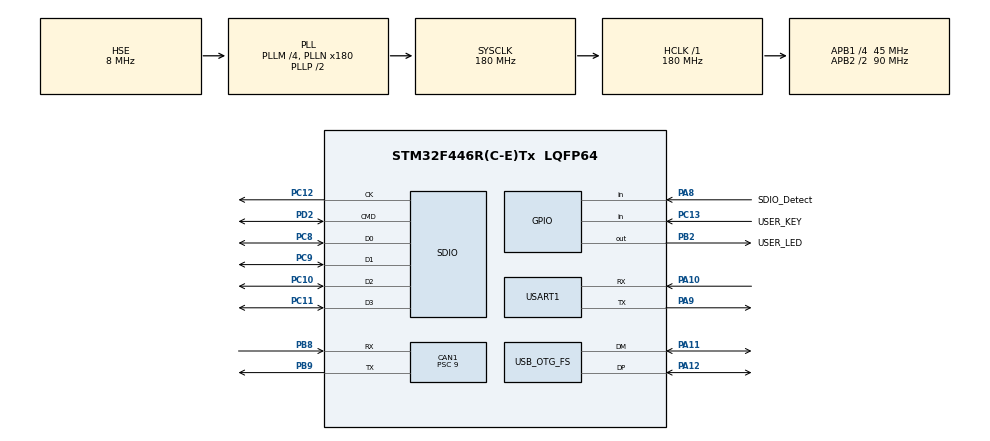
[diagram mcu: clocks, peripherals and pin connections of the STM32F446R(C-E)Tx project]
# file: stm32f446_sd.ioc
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CAN1.BS1=CAN_BS1_13TQ
CAN1.BS2=CAN_BS2_6TQ
CAN1.CalculateBaudRate=250000
CAN1.CalculateTimeBit=4000
CAN1.CalculateTimeQuantum=200.0
CAN1.Mode=CAN_MODE_LOOPBACK
CAN1.Prescaler=9
Dma.Request0=SDIO_RX
Dma.Request1=SDIO_TX
Dma.Request2=USART1_RX
Dma.Request3=USART1_TX
Dma.SDIO_RX.0.Direction=DMA_PERIPH_TO_MEMORY
Dma.SDIO_RX.0.FIFOMode=DMA_FIFOMODE_ENABLE
Dma.SDIO_RX.0.FIFOThreshold=DMA_FIFO_THRESHOLD_FULL
Dma.SDIO_RX.0.Instance=DMA2_Stream3
Dma.SDIO_RX.0.MemBurst=DMA_MBURST_INC4
Dma.SDIO_RX.0.MemDataAlignment=DMA_MDATAALIGN_WORD
Dma.SDIO_RX.0.MemInc=DMA_MINC_ENABLE
Dma.SDIO_RX.0.Mode=DMA_PFCTRL
Dma.SDIO_RX.0.PeriphBurst=DMA_PBURST_INC4
Dma.SDIO_RX.0.PeriphDataAlignment=DMA_PDATAALIGN_WORD
Dma.SDIO_RX.0.PeriphInc=DMA_PINC_DISABLE
Dma.SDIO_RX.0.Priority=DMA_PRIORITY_LOW
Dma.SDIO_TX.1.Direction=DMA_MEMORY_TO_PERIPH
Dma.SDIO_TX.1.FIFOMode=DMA_FIFOMODE_ENABLE
Dma.SDIO_TX.1.FIFOThreshold=DMA_FIFO_THRESHOLD_FULL
Dma.SDIO_TX.1.Instance=DMA2_Stream6
Dma.SDIO_TX.1.MemBurst=DMA_MBURST_INC4
Dma.SDIO_TX.1.MemDataAlignment=DMA_MDATAALIGN_WORD
Dma.SDIO_TX.1.MemInc=DMA_MINC_ENABLE
Dma.SDIO_TX.1.Mode=DMA_PFCTRL
Dma.SDIO_TX.1.PeriphBurst=DMA_PBURST_INC4
Dma.SDIO_TX.1.PeriphDataAlignment=DMA_PDATAALIGN_WORD
Dma.SDIO_TX.1.PeriphInc=DMA_PINC_DISABLE
Dma.SDIO_TX.1.Priority=DMA_PRIORITY_LOW
Dma.USART1_RX.2.Direction=DMA_PERIPH_TO_MEMORY
Dma.USART1_RX.2.FIFOMode=DMA_FIFOMODE_DISABLE
Dma.USART1_RX.2.Instance=DMA2_Stream2
Dma.USART1_RX.2.MemDataAlignment=DMA_MDATAALIGN_BYTE
Dma.USART1_RX.2.MemInc=DMA_MINC_ENABLE
Dma.USART1_RX.2.Mode=DMA_NORMAL
Dma.USART1_RX.2.PeriphDataAlignment=DMA_PDATAALIGN_BYTE
Dma.USART1_RX.2.PeriphInc=DMA_PINC_DISABLE
Dma.USART1_RX.2.Priority=DMA_PRIORITY_LOW
Dma.USART1_TX.3.Direction=DMA_MEMORY_TO_PERIPH
Dma.USART1_TX.3.FIFOMode=DMA_FIFOMODE_DISABLE
Dma.USART1_TX.3.Instance=DMA2_Stream7
Dma.USART1_TX.3.MemDataAlignment=DMA_MDATAALIGN_BYTE
Dma.USART1_TX.3.MemInc=DMA_MINC_ENABLE
Dma.USART1_TX.3.Mode=DMA_NORMAL
Dma.USART1_TX.3.PeriphDataAlignment=DMA_PDATAALIGN_BYTE
Dma.USART1_TX.3.PeriphInc=DMA_PINC_DISABLE
Dma.USART1_TX.3.Priority=DMA_PRIORITY_LOW
FATFS.BSP.number=1
FATFS.USE_DMA_CODE_SD=1
FATFS0.BSP.STBoard=false
FATFS0.BSP.api=Unknown
FATFS0.BSP.instance=PA8
FATFS0.BSP.ip=GPIO
FATFS0.BSP.mode=Input
FATFS0.BSP.name=Detect_SDIO
FATFS0.BSP.solution=PA8
Mcu.Family=STM32F4
Mcu.Name=STM32F446R(C-E)Tx
Mcu.Package=LQFP64
NVIC.DMA2_Stream2_IRQn=true\:0\:0\:false\:false\:true\:false\:true\:true
NVIC.DMA2_Stream3_IRQn=true\:0\:0\:false\:false\:true\:false\:true\:true
NVIC.DMA2_Stream6_IRQn=true\:0\:0\:false\:false\:true\:false\:true\:true
NVIC.DMA2_Stream7_IRQn=true\:0\:0\:false\:false\:true\:false\:true\:true
NVIC.OTG_FS_IRQn=true\:0\:0\:false\:false\:true\:false\:true\:true
NVIC.PriorityGroup=NVIC_PRIORITYGROUP_4
NVIC.SDIO_IRQn=true\:0\:0\:false\:false\:true\:true\:true\:true
NVIC.USART1_IRQn=true\:0\:0\:false\:false\:true\:true\:true\:true
PA10.Mode=Asynchronous
PA10.Signal=USART1_RX
PA11.Mode=Device_Only
PA11.Signal=USB_OTG_FS_DM
PA12.Mode=Device_Only
PA12.Signal=USB_OTG_FS_DP
PA13.Mode=Serial_Wire
PA13.Signal=SYS_JTMS-SWDIO
PA14.Mode=Serial_Wire
PA14.Signal=SYS_JTCK-SWCLK
PA8.GPIO_Label=SDIO_Detect
PA8.GPIO_PuPd=GPIO_PULLUP
PA8.Signal=GPIO_Input
PA9.Mode=Asynchronous
PA9.Signal=USART1_TX
PB2.GPIO_Label=USER_LED
PB2.Signal=GPIO_Output
PB8.Mode=CAN_Activate
PB8.Signal=CAN1_RX
PB9.Mode=CAN_Activate
PB9.Signal=CAN1_TX
PC10.Mode=SD_4_bits_Wide_bus
PC10.Signal=SDIO_D2
PC11.Mode=SD_4_bits_Wide_bus
PC11.Signal=SDIO_D3
PC12.Mode=SD_4_bits_Wide_bus
PC12.Signal=SDIO_CK
PC13.GPIO_Label=USER_KEY
PC13.GPIO_PuPd=GPIO_PULLDOWN
PC13.Signal=GPIO_Input
PC8.Mode=SD_4_bits_Wide_bus
PC8.Signal=SDIO_D0
PC9.Mode=SD_4_bits_Wide_bus
PC9.Signal=SDIO_D1
PD2.Mode=SD_4_bits_Wide_bus
PD2.Signal=SDIO_CMD
PH0-OSC_IN.Mode=HSE-External-Oscillator
PH0-OSC_IN.Signal=RCC_OSC_IN
PH1-OSC_OUT.Mode=HSE-External-Oscillator
PH1-OSC_OUT.Signal=RCC_OSC_OUT
ProjectManager.HeapSize=0x400
ProjectManager.StackSize=0x800
ProjectManager.TargetToolchain=STM32CubeIDE
RCC.AHBFreq_Value=180000000
RCC.APB1CLKDivider=RCC_HCLK_DIV4
RCC.APB1Freq_Value=45000000
RCC.APB1TimFreq_Value=90000000
RCC.APB2CLKDivider=RCC_HCLK_DIV2
RCC.APB2Freq_Value=90000000
RCC.APB2TimFreq_Value=180000000
RCC.CortexFreq_Value=180000000
RCC.HCLKFreq_Value=180000000
RCC.HSE_VALUE=8000000
RCC.PLLM=4
RCC.PLLN=180
RCC.PLLSAIM=4
RCC.PLLSAIN=96
RCC.PLLSAIP=RCC_PLLSAIP_DIV4
RCC.PLLSourceVirtual=RCC_PLLSOURCE_HSE
RCC.RCC_RTC_Clock_SourceVirtual=RCC_RTCCLKSOURCE_LSE
RCC.SYSCLKFreq_VALUE=180000000
RCC.SYSCLKSource=RCC_SYSCLKSOURCE_PLLCLK
RCC.USBCLockSelection=RCC_CLK48CLKSOURCE_PLLSAIP
RCC.USBFreq_Value=48000000
RCC.VCOOutputFreq_Value=360000000
USART1.VirtualMode=VM_ASYNC
USART1.WordLength=WORDLENGTH_8B
USB_DEVICE.CLASS_NAME_FS=CDC
USB_DEVICE.VirtualMode-CDC_FS=Cdc
USB_DEVICE.VirtualModeFS=Cdc_FS
USB_OTG_FS.VirtualMode=Device_Only
VP_FATFS_VS_SDIO.Mode=SDIO
VP_USB_DEVICE_VS_USB_DEVICE_CDC_FS.Mode=CDC_FS
board=custom

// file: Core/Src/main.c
/* USER CODE BEGIN Header */
/**
  ******************************************************************************
  * @file           : main.c
  * @brief          : Main program body
  ******************************************************************************
  * @attention
  *
  * Copyright (c) 2024 STMicroelectronics.
  * All rights reserved.
  *
  * This software is licensed under terms that can be found in the LICENSE file
  * in the root directory of this software component.
  * If no LICENSE file comes with this software, it is provided AS-IS.
  *
  ******************************************************************************
  */
/* USER CODE END Header */
#include "main.h"
#include "fatfs.h"
#include "usb_device.h"

/* USER CODE BEGIN Includes */
#include "usbd_cdc_if.h"
/* USER CODE END Includes */

CAN_HandleTypeDef hcan1;

SD_HandleTypeDef hsd;
DMA_HandleTypeDef hdma_sdio_rx;
DMA_HandleTypeDef hdma_sdio_tx;

UART_HandleTypeDef huart1;
DMA_HandleTypeDef hdma_usart1_rx;
DMA_HandleTypeDef hdma_usart1_tx;

void SystemClock_Config(void);
void PeriphCommonClock_Config(void);
static void MX_GPIO_Init(void);
static void MX_DMA_Init(void);
static void MX_SDIO_SD_Init(void);
static void MX_CAN1_Init(void);
static void MX_USART1_UART_Init(void);

int main(void)
{
  /* USER CODE BEGIN 1 */
  uint8_t print_buf[] = "Hello, world!\n";
  size_t print_len = sizeof(print_buf);
  /* USER CODE END 1 */

  /* MCU Configuration--------------------------------------------------------*/

  /* Reset of all peripherals, Initializes the Flash interface and the Systick. */
  HAL_Init();

  /* Configure the system clock */
  SystemClock_Config();

/* Configure the peripherals common clocks */
  PeriphCommonClock_Config();

  /* Initialize all configured peripherals */
  MX_GPIO_Init();
  MX_DMA_Init();
  MX_USB_DEVICE_Init();
  MX_SDIO_SD_Init();
  MX_FATFS_Init();
  MX_CAN1_Init();
  MX_USART1_UART_Init();

  /* Infinite loop */
  /* USER CODE BEGIN WHILE */
  while (1)
  {
    HAL_Delay(500);
    if (!HAL_GPIO_ReadPin(USER_KEY_GPIO_Port, USER_KEY_Pin))
    {
      CDC_Transmit_FS(print_buf, print_len);
      HAL_UART_Transmit_DMA(&huart1, print_buf, print_len);
      HAL_GPIO_TogglePin(USER_LED_GPIO_Port, USER_LED_Pin);
    }
    /* USER CODE END WHILE */

  }
}

void SystemClock_Config(void)
{
  RCC_OscInitTypeDef RCC_OscInitStruct = {0};
  RCC_ClkInitTypeDef RCC_ClkInitStruct = {0};

  /** Configure the main internal regulator output voltage
  */
  __HAL_RCC_PWR_CLK_ENABLE();
  __HAL_PWR_VOLTAGESCALING_CONFIG(PWR_REGULATOR_VOLTAGE_SCALE1);

  /** Initializes the RCC Oscillators according to the specified parameters
  * in the RCC_OscInitTypeDef structure.
  */
  RCC_OscInitStruct.OscillatorType = RCC_OSCILLATORTYPE_HSE;
  RCC_OscInitStruct.HSEState = RCC_HSE_ON;
  RCC_OscInitStruct.PLL.PLLState = RCC_PLL_ON;
  RCC_OscInitStruct.PLL.PLLSource = RCC_PLLSOURCE_HSE;
  RCC_OscInitStruct.PLL.PLLM = 4;
  RCC_OscInitStruct.PLL.PLLN = 180;
  RCC_OscInitStruct.PLL.PLLP = RCC_PLLP_DIV2;
  RCC_OscInitStruct.PLL.PLLQ = 2;
  RCC_OscInitStruct.PLL.PLLR = 2;
  if (HAL_RCC_OscConfig(&RCC_OscInitStruct) != HAL_OK)
  {
    Error_Handler();
  }

  /** Activate the Over-Drive mode
  */
  if (HAL_PWREx_EnableOverDrive() != HAL_OK)
  {
    Error_Handler();
  }

  /** Initializes the CPU, AHB and APB buses clocks
  */
  RCC_ClkInitStruct.ClockType = RCC_CLOCKTYPE_HCLK|RCC_CLOCKTYPE_SYSCLK
                              |RCC_CLOCKTYPE_PCLK1|RCC_CLOCKTYPE_PCLK2;
  RCC_ClkInitStruct.SYSCLKSource = RCC_SYSCLKSOURCE_PLLCLK;
  RCC_ClkInitStruct.AHBCLKDivider = RCC_SYSCLK_DIV1;
  RCC_ClkInitStruct.APB1CLKDivider = RCC_HCLK_DIV4;
  RCC_ClkInitStruct.APB2CLKDivider = RCC_HCLK_DIV2;

  if (HAL_RCC_ClockConfig(&RCC_ClkInitStruct, FLASH_LATENCY_5) != HAL_OK)
  {
    Error_Handler();
  }
}

void PeriphCommonClock_Config(void)
{
  RCC_PeriphCLKInitTypeDef PeriphClkInitStruct = {0};

  /** Initializes the peripherals clock
  */
  PeriphClkInitStruct.PeriphClockSelection = RCC_PERIPHCLK_SDIO|RCC_PERIPHCLK_CLK48;
  PeriphClkInitStruct.PLLSAI.PLLSAIM = 4;
  PeriphClkInitStruct.PLLSAI.PLLSAIN = 96;
  PeriphClkInitStruct.PLLSAI.PLLSAIQ = 2;
  PeriphClkInitStruct.PLLSAI.PLLSAIP = RCC_PLLSAIP_DIV4;
  PeriphClkInitStruct.PLLSAIDivQ = 1;
  PeriphClkInitStruct.Clk48ClockSelection = RCC_CLK48CLKSOURCE_PLLSAIP;
  PeriphClkInitStruct.SdioClockSelection = RCC_SDIOCLKSOURCE_CLK48;
  if (HAL_RCCEx_PeriphCLKConfig(&PeriphClkInitStruct) != HAL_OK)
  {
    Error_Handler();
  }
}

static void MX_CAN1_Init(void)
{

  hcan1.Instance = CAN1;
  hcan1.Init.Prescaler = 9;
  hcan1.Init.Mode = CAN_MODE_LOOPBACK;
  hcan1.Init.SyncJumpWidth = CAN_SJW_1TQ;
  hcan1.Init.TimeSeg1 = CAN_BS1_13TQ;
  hcan1.Init.TimeSeg2 = CAN_BS2_6TQ;
  hcan1.Init.TimeTriggeredMode = DISABLE;
  hcan1.Init.AutoBusOff = DISABLE;
  hcan1.Init.AutoWakeUp = DISABLE;
  hcan1.Init.AutoRetransmission = DISABLE;
  hcan1.Init.ReceiveFifoLocked = DISABLE;
  hcan1.Init.TransmitFifoPriority = DISABLE;
  if (HAL_CAN_Init(&hcan1) != HAL_OK)
  {
    Error_Handler();
  }

}

static void MX_SDIO_SD_Init(void)
{

  hsd.Instance = SDIO;
  hsd.Init.ClockEdge = SDIO_CLOCK_EDGE_RISING;
  hsd.Init.ClockBypass = SDIO_CLOCK_BYPASS_DISABLE;
  hsd.Init.ClockPowerSave = SDIO_CLOCK_POWER_SAVE_DISABLE;
  hsd.Init.BusWide = SDIO_BUS_WIDE_4B;
  hsd.Init.HardwareFlowControl = SDIO_HARDWARE_FLOW_CONTROL_DISABLE;
  hsd.Init.ClockDiv = 0;

}

static void MX_USART1_UART_Init(void)
{

  huart1.Instance = USART1;
  huart1.Init.BaudRate = 115200;
  huart1.Init.WordLength = UART_WORDLENGTH_8B;
  huart1.Init.StopBits = UART_STOPBITS_1;
  huart1.Init.Parity = UART_PARITY_NONE;
  huart1.Init.Mode = UART_MODE_TX_RX;
  huart1.Init.HwFlowCtl = UART_HWCONTROL_NONE;
  huart1.Init.OverSampling = UART_OVERSAMPLING_16;
  if (HAL_UART_Init(&huart1) != HAL_OK)
  {
    Error_Handler();
  }

}

static void MX_DMA_Init(void)
{

  /* DMA controller clock enable */
  __HAL_RCC_DMA2_CLK_ENABLE();

  /* DMA interrupt init */
  /* DMA2_Stream2_IRQn interrupt configuration */
  HAL_NVIC_SetPriority(DMA2_Stream2_IRQn, 0, 0);
  HAL_NVIC_EnableIRQ(DMA2_Stream2_IRQn);
  /* DMA2_Stream3_IRQn interrupt configuration */
  HAL_NVIC_SetPriority(DMA2_Stream3_IRQn, 0, 0);
  HAL_NVIC_EnableIRQ(DMA2_Stream3_IRQn);
  /* DMA2_Stream6_IRQn interrupt configuration */
  HAL_NVIC_SetPriority(DMA2_Stream6_IRQn, 0, 0);
  HAL_NVIC_EnableIRQ(DMA2_Stream6_IRQn);
  /* DMA2_Stream7_IRQn interrupt configuration */
  HAL_NVIC_SetPriority(DMA2_Stream7_IRQn, 0, 0);
  HAL_NVIC_EnableIRQ(DMA2_Stream7_IRQn);

}

static void MX_GPIO_Init(void)
{
  GPIO_InitTypeDef GPIO_InitStruct = {0};

  /* GPIO Ports Clock Enable */
  __HAL_RCC_GPIOC_CLK_ENABLE();
  __HAL_RCC_GPIOH_CLK_ENABLE();
  __HAL_RCC_GPIOB_CLK_ENABLE();
  __HAL_RCC_GPIOA_CLK_ENABLE();
  __HAL_RCC_GPIOD_CLK_ENABLE();

  /*Configure GPIO pin Output Level */
  HAL_GPIO_WritePin(USER_LED_GPIO_Port, USER_LED_Pin, GPIO_PIN_RESET);

  /*Configure GPIO pin : USER_KEY_Pin */
  GPIO_InitStruct.Pin = USER_KEY_Pin;
  GPIO_InitStruct.Mode = GPIO_MODE_INPUT;
  GPIO_InitStruct.Pull = GPIO_PULLDOWN;
  HAL_GPIO_Init(USER_KEY_GPIO_Port, &GPIO_InitStruct);

  /*Configure GPIO pin : USER_LED_Pin */
  GPIO_InitStruct.Pin = USER_LED_Pin;
  GPIO_InitStruct.Mode = GPIO_MODE_OUTPUT_PP;
  GPIO_InitStruct.Pull = GPIO_NOPULL;
  GPIO_InitStruct.Speed = GPIO_SPEED_FREQ_LOW;
  HAL_GPIO_Init(USER_LED_GPIO_Port, &GPIO_InitStruct);

  /*Configure GPIO pin : SDIO_Detect_Pin */
  GPIO_InitStruct.Pin = SDIO_Detect_Pin;
  GPIO_InitStruct.Mode = GPIO_MODE_INPUT;
  GPIO_InitStruct.Pull = GPIO_PULLUP;
  HAL_GPIO_Init(SDIO_Detect_GPIO_Port, &GPIO_InitStruct);

}

void Error_Handler(void)
{
  __disable_irq();
  while (1)
  {
  }
}
